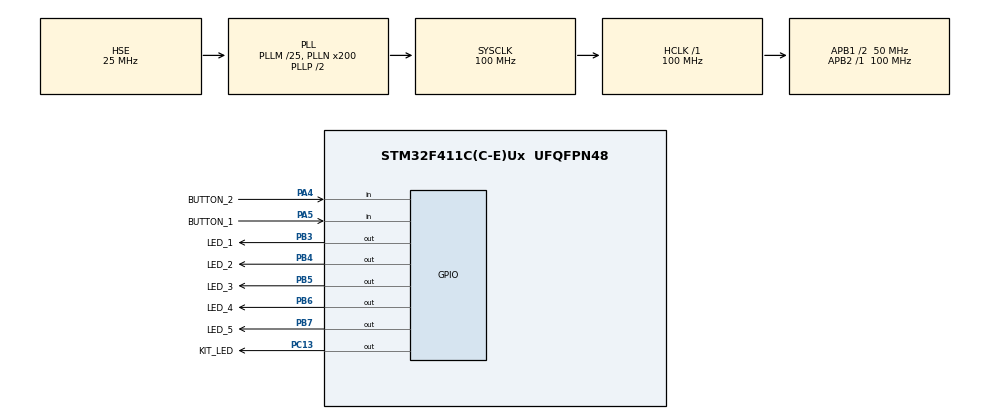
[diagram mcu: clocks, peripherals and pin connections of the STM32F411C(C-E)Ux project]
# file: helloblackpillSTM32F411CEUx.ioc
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Mcu.Family=STM32F4
Mcu.Name=STM32F411C(C-E)Ux
Mcu.Package=UFQFPN48
NVIC.PriorityGroup=NVIC_PRIORITYGROUP_4
NVIC.TIM2_IRQn=true\:0\:0\:false\:false\:true\:true\:true\:true
PA13.Mode=Serial_Wire
PA13.Signal=SYS_JTMS-SWDIO
PA14.Mode=Serial_Wire
PA14.Signal=SYS_JTCK-SWCLK
PA4.GPIO_Label=BUTTON_2
PA4.Signal=GPIO_Input
PA5.GPIO_Label=BUTTON_1
PA5.Signal=GPIO_Input
PB3.GPIO_Label=LED_1
PB3.Signal=GPIO_Output
PB4.GPIO_Label=LED_2
PB4.Signal=GPIO_Output
PB5.GPIO_Label=LED_3
PB5.Signal=GPIO_Output
PB6.GPIO_Label=LED_4
PB6.Signal=GPIO_Output
PB7.GPIO_Label=LED_5
PB7.Signal=GPIO_Output
PC13-ANTI_TAMP.GPIO_Label=KIT_LED
PC13-ANTI_TAMP.Signal=GPIO_Output
PC14-OSC32_IN.Mode=LSE-External-Oscillator
PC14-OSC32_IN.Signal=RCC_OSC32_IN
PC15-OSC32_OUT.Mode=LSE-External-Oscillator
PC15-OSC32_OUT.Signal=RCC_OSC32_OUT
PH0\ -\ OSC_IN.Mode=HSE-External-Oscillator
PH0\ -\ OSC_IN.Signal=RCC_OSC_IN
PH1\ -\ OSC_OUT.Mode=HSE-External-Oscillator
PH1\ -\ OSC_OUT.Signal=RCC_OSC_OUT
ProjectManager.HeapSize=0x200
ProjectManager.StackSize=0x400
ProjectManager.TargetToolchain=Makefile
RCC.48MHZClocksFreq_Value=50000000
RCC.AHBFreq_Value=100000000
RCC.APB1CLKDivider=RCC_HCLK_DIV2
RCC.APB1Freq_Value=50000000
RCC.APB1TimFreq_Value=100000000
RCC.APB2Freq_Value=100000000
RCC.APB2TimFreq_Value=100000000
RCC.CortexFreq_Value=100000000
RCC.HCLKFreq_Value=100000000
RCC.HSE_VALUE=25000000
RCC.HSI_VALUE=16000000
RCC.PLLM=25
RCC.PLLN=200
RCC.PLLSourceVirtual=RCC_PLLSOURCE_HSE
RCC.SYSCLKFreq_VALUE=100000000
RCC.SYSCLKSource=RCC_SYSCLKSOURCE_PLLCLK
RCC.VCOOutputFreq_Value=200000000
TIM2.Period=1030
TIM2.Prescaler=7200-1
VP_TIM2_VS_ClockSourceINT.Mode=Internal
board=custom

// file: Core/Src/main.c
/* USER CODE BEGIN Header */
/**
  ******************************************************************************
  * @file           : main.c
  * @brief          : Main program body
  ******************************************************************************
  * @attention
  *
  * Copyright (c) 2022 STMicroelectronics.
  * All rights reserved.
  *
  * This software is licensed under terms that can be found in the LICENSE file
  * in the root directory of this software component.
  * If no LICENSE file comes with this software, it is provided AS-IS.
  *
  ******************************************************************************
  */
/* USER CODE END Header */
#include "main.h"
#include "button.h"

TIM_HandleTypeDef htim2;

/* USER CODE BEGIN PV */
uint16_t leds = 0;
uint16_t PeriodTimer = 1030;
/* USER CODE END PV */

void SystemClock_Config(void);
static void MX_GPIO_Init(void);
static void MX_TIM2_Init(void);

int main(void)
{

  /* MCU Configuration--------------------------------------------------------*/

  /* Reset of all peripherals, Initializes the Flash interface and the Systick. */
  HAL_Init();

  /* Configure the system clock */
  SystemClock_Config();

  /* Initialize all configured peripherals */
  MX_GPIO_Init();
  MX_TIM2_Init();
  /* USER CODE BEGIN 2 */

  // Função de start do timer com o ponteiro para o timer 2
  HAL_TIM_Base_Start_TT (&htim2);
  /* USER CODE END 2 */

  /* Infinite loop */
  /* USER CODE BEGIN WHILE */
  while (1)
  {
    //Bottão 1
    if( button_release( GPIOA, GPIO_PIN_5, 0) )
    {
      PeriodTimer = PeriodTimer + 103;
    }

    //Bottão 2
    if( button_release( GPIOA, GPIO_PIN_6, 0) )
    {
      PeriodTimer = PeriodTimer - 103
    }

    // Altera o estado lógico do led da placa a cada 200ms
    HAL_GPIO_TogglePin(KIT_LED_GPIO_Port, KIT_LED_Pin);
    HAL_Delay(200);

    /* USER CODE END WHILE */

  }
}

void SystemClock_Config(void)
{
  RCC_OscInitTypeDef RCC_OscInitStruct = {0};
  RCC_ClkInitTypeDef RCC_ClkInitStruct = {0};

  /** Configure the main internal regulator output voltage
  */
  __HAL_RCC_PWR_CLK_ENABLE();
  __HAL_PWR_VOLTAGESCALING_CONFIG(PWR_REGULATOR_VOLTAGE_SCALE1);

  /** Initializes the RCC Oscillators according to the specified parameters
  * in the RCC_OscInitTypeDef structure.
  */
  RCC_OscInitStruct.OscillatorType = RCC_OSCILLATORTYPE_HSE;
  RCC_OscInitStruct.HSEState = RCC_HSE_ON;
  RCC_OscInitStruct.PLL.PLLState = RCC_PLL_ON;
  RCC_OscInitStruct.PLL.PLLSource = RCC_PLLSOURCE_HSE;
  RCC_OscInitStruct.PLL.PLLM = 25;
  RCC_OscInitStruct.PLL.PLLN = 200;
  RCC_OscInitStruct.PLL.PLLP = RCC_PLLP_DIV2;
  RCC_OscInitStruct.PLL.PLLQ = 4;
  if (HAL_RCC_OscConfig(&RCC_OscInitStruct) != HAL_OK)
  {
    Error_Handler();
  }

  /** Initializes the CPU, AHB and APB buses clocks
  */
  RCC_ClkInitStruct.ClockType = RCC_CLOCKTYPE_HCLK|RCC_CLOCKTYPE_SYSCLK
                              |RCC_CLOCKTYPE_PCLK1|RCC_CLOCKTYPE_PCLK2;
  RCC_ClkInitStruct.SYSCLKSource = RCC_SYSCLKSOURCE_PLLCLK;
  RCC_ClkInitStruct.AHBCLKDivider = RCC_SYSCLK_DIV1;
  RCC_ClkInitStruct.APB1CLKDivider = RCC_HCLK_DIV2;
  RCC_ClkInitStruct.APB2CLKDivider = RCC_HCLK_DIV1;

  if (HAL_RCC_ClockConfig(&RCC_ClkInitStruct, FLASH_LATENCY_3) != HAL_OK)
  {
    Error_Handler();
  }
}

static void MX_TIM2_Init(void)
{

  TIM_ClockConfigTypeDef sClockSourceConfig = {0};
  TIM_MasterConfigTypeDef sMasterConfig = {0};

  htim2.Instance = TIM2;
  htim2.Init.Prescaler = 7200-1;
  htim2.Init.CounterMode = TIM_COUNTERMODE_UP;
  htim2.Init.Period = PeriodTimer;
  htim2.Init.ClockDivision = TIM_CLOCKDIVISION_DIV1;
  htim2.Init.AutoReloadPreload = TIM_AUTORELOAD_PRELOAD_DISABLE;
  if (HAL_TIM_Base_Init(&htim2) != HAL_OK)
  {
    Error_Handler();
  }
  sClockSourceConfig.ClockSource = TIM_CLOCKSOURCE_INTERNAL;
  if (HAL_TIM_ConfigClockSource(&htim2, &sClockSourceConfig) != HAL_OK)
  {
    Error_Handler();
  }
  sMasterConfig.MasterOutputTrigger = TIM_TRGO_RESET;
  sMasterConfig.MasterSlaveMode = TIM_MASTERSLAVEMODE_DISABLE;
  if (HAL_TIMEx_MasterConfigSynchronization(&htim2, &sMasterConfig) != HAL_OK)
  {
    Error_Handler();
  }

}

static void MX_GPIO_Init(void)
{
  GPIO_InitTypeDef GPIO_InitStruct = {0};

  /* GPIO Ports Clock Enable */
  __HAL_RCC_GPIOC_CLK_ENABLE();
  __HAL_RCC_GPIOH_CLK_ENABLE();
  __HAL_RCC_GPIOA_CLK_ENABLE();
  __HAL_RCC_GPIOB_CLK_ENABLE();

  /*Configure GPIO pin Output Level */
  HAL_GPIO_WritePin(KIT_LED_GPIO_Port, KIT_LED_Pin, GPIO_PIN_RESET);

  /*Configure GPIO pin Output Level */
  HAL_GPIO_WritePin(GPIOB, LED_1_Pin|LED_2_Pin|LED_3_Pin|LED_4_Pin
                          |LED_5_Pin, GPIO_PIN_RESET);

  /*Configure GPIO pin : KIT_LED_Pin */
  GPIO_InitStruct.Pin = KIT_LED_Pin;
  GPIO_InitStruct.Mode = GPIO_MODE_OUTPUT_PP;
  GPIO_InitStruct.Pull = GPIO_NOPULL;
  GPIO_InitStruct.Speed = GPIO_SPEED_FREQ_LOW;
  HAL_GPIO_Init(KIT_LED_GPIO_Port, &GPIO_InitStruct);

  /*Configure GPIO pins : BUTTON_2_Pin BUTTON_1_Pin */
  GPIO_InitStruct.Pin = BUTTON_2_Pin|BUTTON_1_Pin;
  GPIO_InitStruct.Mode = GPIO_MODE_INPUT;
  GPIO_InitStruct.Pull = GPIO_NOPULL;
  HAL_GPIO_Init(GPIOA, &GPIO_InitStruct);

  /*Configure GPIO pins : LED_1_Pin LED_2_Pin LED_3_Pin LED_4_Pin
                           LED_5_Pin */
  GPIO_InitStruct.Pin = LED_1_Pin|LED_2_Pin|LED_3_Pin|LED_4_Pin
                          |LED_5_Pin;
  GPIO_InitStruct.Mode = GPIO_MODE_OUTPUT_PP;
  GPIO_InitStruct.Pull = GPIO_NOPULL;
  GPIO_InitStruct.Speed = GPIO_SPEED_FREQ_LOW;
  HAL_GPIO_Init(GPIOB, &GPIO_InitStruct);

}

/* USER CODE BEGIN 4 */

//Função de deverá ser acionada quando o timer for acionado

void HAL_TIM _ PeriodElapsedCallback( TIM_HandleTypeDef*htim )
{
  leds = ( leds == 0 ) ? ( 1 << 3 ) : ( ( leds << 1 ) & 0x1F << 3 );
  HAL_GPIO_WritePin(GPIOB, 0X1F << 3, 0);
  HAL_GPIO_WritePin(GPIOB, leds, 1);
}
/* USER CODE END 4 */

void Error_Handler(void)
{
  __disable_irq();
  while (1)
  {
  }
}
